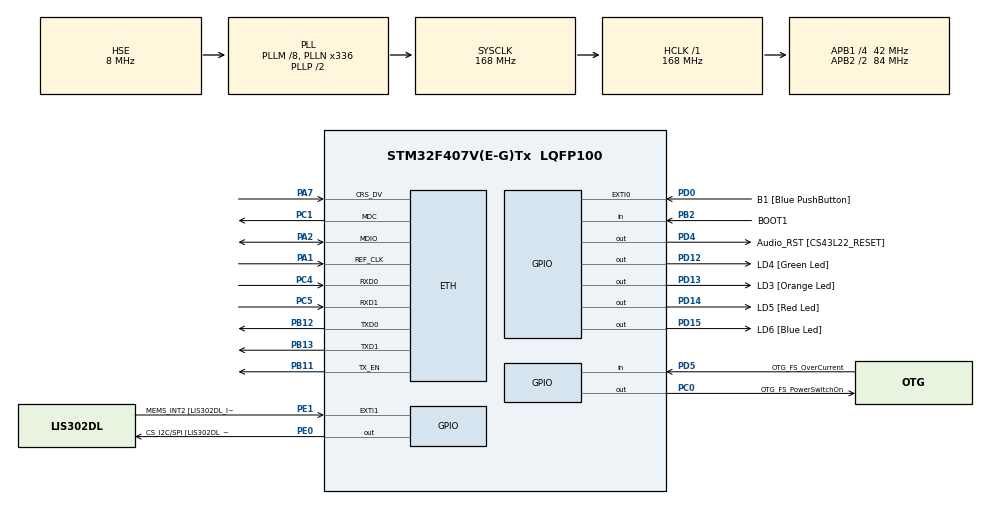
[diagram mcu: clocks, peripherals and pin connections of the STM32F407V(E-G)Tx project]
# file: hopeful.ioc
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ETH.MediaInterface=ETH_MEDIA_INTERFACE_RMII
FREERTOS.Tasks01=defaultTask,0,128,StartDefaultTask
Mcu.Family=STM32F4
Mcu.Name=STM32F407V(E-G)Tx
Mcu.Package=LQFP100
NVIC.ETH_IRQn=true\:5\:0\:false
NVIC.PriorityGroup=NVIC_PRIORITYGROUP_4
PA1.Mode=RMII
PA1.Signal=ETH_REF_CLK
PA10.GPIO_Label=OTG_FS_ID
PA10.GPIO_Mode=GPIO_MODE_AF_PP
PA10.GPIO_PuPd=GPIO_NOPULL
PA10.GPIO_Speed=GPIO_SPEED_LOW
PA10.Signal=USB_OTG_FS_ID
PA11.GPIO_Label=OTG_FS_DM
PA11.GPIO_Mode=GPIO_MODE_AF_PP
PA11.GPIO_PuPd=GPIO_NOPULL
PA11.GPIO_Speed=GPIO_SPEED_LOW
PA11.Signal=USB_OTG_FS_DM
PA12.GPIO_Label=OTG_FS_DP
PA12.GPIO_Mode=GPIO_MODE_AF_PP
PA12.GPIO_PuPd=GPIO_NOPULL
PA12.GPIO_Speed=GPIO_SPEED_LOW
PA12.Signal=USB_OTG_FS_DP
PA13.GPIO_Label=SWDIO
PA13.Mode=Trace-Asynchronous_SW
PA13.Signal=SYS_JTMS-SWDIO
PA14.GPIO_Label=SWCLK
PA14.Mode=Trace-Asynchronous_SW
PA14.Signal=SYS_JTCK-SWCLK
PA2.Mode=RMII
PA2.Signal=ETH_MDIO
PA4.GPIO_Label=I2S3_WS [CS43L22_LRCK]
PA4.GPIO_Mode=GPIO_MODE_AF_PP
PA4.GPIO_PuPd=GPIO_NOPULL
PA4.GPIO_Speed=GPIO_SPEED_LOW
PA4.Signal=I2S3_WS
PA5.GPIO_Label=SPI1_SCK [LIS302DL_SCL/SPC]
PA5.GPIO_Mode=GPIO_MODE_AF_PP
PA5.GPIO_PuPd=GPIO_NOPULL
PA5.GPIO_Speed=GPIO_SPEED_LOW
PA5.Signal=SPI1_SCK
PA6.GPIO_Label=SPI1_MISO [LIS302DL_SDO]
PA6.GPIO_Mode=GPIO_MODE_AF_PP
PA6.GPIO_PuPd=GPIO_NOPULL
PA6.GPIO_Speed=GPIO_SPEED_LOW
PA6.Signal=SPI1_MISO
PA7.Mode=RMII
PA7.Signal=ETH_CRS_DV
PA9.GPIO_Label=VBUS_FS
PA9.GPIO_Mode=GPIO_MODE_INPUT
PA9.GPIO_PuPd=GPIO_NOPULL
PA9.Signal=USB_OTG_FS_VBUS
PB10.GPIO_Label=CLK_IN [MP45DT02_CLK]
PB10.GPIO_Mode=GPIO_MODE_AF_PP
PB10.GPIO_PuPd=GPIO_NOPULL
PB10.GPIO_Speed=GPIO_SPEED_LOW
PB10.Signal=I2S2_CK
PB11.Mode=RMII
PB11.Signal=ETH_TX_EN
PB12.Mode=RMII
PB12.Signal=ETH_TXD0
PB13.Mode=RMII
PB13.Signal=ETH_TXD1
PB15.GPIO_Label=PDM_OUT [MP45DT02_DOUT]
PB15.GPIO_Mode=GPIO_MODE_AF_PP
PB15.GPIO_PuPd=GPIO_NOPULL
PB15.GPIO_Speed=GPIO_SPEED_LOW
PB15.Signal=I2S2_SD
PB2.GPIO_Label=BOOT1
PB2.GPIO_Mode=GPIO_MODE_INPUT
PB2.GPIO_PuPd=GPIO_NOPULL
PB2.Signal=GPIO_Input
PB3.GPIO_Label=SWO
PB3.Mode=Trace-Asynchronous_SW
PB3.Signal=SYS_JTDO-SWO
PB6.GPIO_Label=Audio_SCL [CS43L22_SCL]
PB6.GPIO_Mode=GPIO_MODE_AF_OD
PB6.GPIO_PuPd=GPIO_NOPULL
PB6.GPIO_Speed=GPIO_SPEED_LOW
PB6.Signal=I2C1_SCL
PB9.GPIO_Label=Audio_SDA [CS43L22_SDA]
PB9.GPIO_Mode=GPIO_MODE_AF_OD
PB9.GPIO_PuPd=GPIO_NOPULL
PB9.GPIO_Speed=GPIO_SPEED_LOW
PB9.Signal=I2C1_SDA
PC0.GPIO_Label=OTG_FS_PowerSwitchOn
PC0.GPIO_PuPd=GPIO_NOPULL
PC0.GPIO_Speed=GPIO_SPEED_LOW
PC0.Signal=GPIO_Output
PC1.Mode=RMII
PC1.Signal=ETH_MDC
PC10.GPIO_Label=I2S3_SCK [CS43L22_SCLK]
PC10.GPIO_Mode=GPIO_MODE_AF_PP
PC10.GPIO_PuPd=GPIO_NOPULL
PC10.GPIO_Speed=GPIO_SPEED_LOW
PC10.Signal=I2S3_CK
PC12.GPIO_Label=I2S3_SD [CS43L22_SDIN]
PC12.GPIO_Mode=GPIO_MODE_AF_PP
PC12.GPIO_PuPd=GPIO_NOPULL
PC12.GPIO_Speed=GPIO_SPEED_LOW
PC12.Signal=I2S3_SD
PC14-OSC32_IN.GPIO_Label=PC14-OSC32_IN
PC14-OSC32_IN.Signal=RCC_OSC32_IN
PC15-OSC32_OUT.GPIO_Label=PC15-OSC32_OUT
PC15-OSC32_OUT.Signal=RCC_OSC32_OUT
PC4.Mode=RMII
PC4.Signal=ETH_RXD0
PC5.Mode=RMII
PC5.Signal=ETH_RXD1
PC7.GPIO_Label=I2S3_MCK [CS43L22_MCLK]
PC7.GPIO_Mode=GPIO_MODE_AF_PP
PC7.GPIO_PuPd=GPIO_NOPULL
PC7.GPIO_Speed=GPIO_SPEED_LOW
PC7.Signal=I2S3_MCK
PD0.GPIO_Label=B1 [Blue PushButton]
PD0.GPIO_ModeDefaultEXTI=GPIO_MODE_EVT_RISING
PD0.GPIO_PuPd=GPIO_NOPULL
PD0.Signal=GPXTI0
PD12.GPIO_Label=LD4 [Green Led]
PD12.GPIO_PuPd=GPIO_NOPULL
PD12.GPIO_Speed=GPIO_SPEED_LOW
PD12.Signal=GPIO_Output
PD13.GPIO_Label=LD3 [Orange Led]
PD13.GPIO_PuPd=GPIO_NOPULL
PD13.GPIO_Speed=GPIO_SPEED_LOW
PD13.Signal=GPIO_Output
PD14.GPIO_Label=LD5 [Red Led]
PD14.GPIO_PuPd=GPIO_NOPULL
PD14.GPIO_Speed=GPIO_SPEED_LOW
PD14.Signal=GPIO_Output
PD15.GPIO_Label=LD6 [Blue Led]
PD15.GPIO_PuPd=GPIO_NOPULL
PD15.GPIO_Speed=GPIO_SPEED_LOW
PD15.Signal=GPIO_Output
PD4.GPIO_Label=Audio_RST [CS43L22_RESET]
PD4.GPIO_PuPd=GPIO_NOPULL
PD4.GPIO_Speed=GPIO_SPEED_LOW
PD4.Signal=GPIO_Output
PD5.GPIO_Label=OTG_FS_OverCurrent
PD5.GPIO_Mode=GPIO_MODE_INPUT
PD5.GPIO_PuPd=GPIO_NOPULL
PD5.Signal=GPIO_Input
PE0.GPIO_Label=CS_I2C/SPI [LIS302DL_CS_I2C/SPI]
PE0.GPIO_PuPd=GPIO_NOPULL
PE0.GPIO_Speed=GPIO_SPEED_LOW
PE0.Signal=GPIO_Output
PE1.GPIO_Label=MEMS_INT2 [LIS302DL_INT2]
PE1.GPIO_ModeDefaultEXTI=GPIO_MODE_EVT_RISING
PE1.GPIO_PuPd=GPIO_NOPULL
PE1.Signal=GPXTI1
PH0-OSC_IN.GPIO_Label=PH0-OSC_IN
PH0-OSC_IN.Mode=HSE-External-Oscillator
PH0-OSC_IN.Signal=RCC_OSC_IN
PH1-OSC_OUT.GPIO_Label=PH1-OSC_OUT
PH1-OSC_OUT.Mode=HSE-External-Oscillator
PH1-OSC_OUT.Signal=RCC_OSC_OUT
ProjectManager.TargetToolchain=TrueSTUDIO
RCC.AHBFreq_Value=168000000
RCC.APB1CLKDivider=RCC_HCLK_DIV4
RCC.APB1Freq_Value=42000000
RCC.APB1TimFreq_Value=84000000
RCC.APB2CLKDivider=RCC_HCLK_DIV2
RCC.APB2Freq_Value=84000000
RCC.APB2TimFreq_Value=168000000
RCC.CortexFreq_Value=168000000
RCC.HCLKFreq_Value=168000000
RCC.HSE_VALUE=8000000
RCC.HSI_VALUE=16000000
RCC.LSE_VALUE=32768
RCC.PLLM=8
RCC.PLLN=336
RCC.PLLQ=7
RCC.PLLSourceVirtual=RCC_PLLSOURCE_HSE
RCC.SYSCLKFreq_VALUE=168000000
RCC.SYSCLKSource=RCC_SYSCLKSOURCE_PLLCLK
RCC.VCOOutputFreq_Value=336000000
VP_FREERTOS_VS_ENABLE.Mode=Enabled
VP_LWIP_VS_Enabled.Mode=Enabled
board=STM32F4DISCOVERY

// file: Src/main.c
/**
  ******************************************************************************
  * File Name          : main.c
  * Description        : Main program body
  ******************************************************************************
  *
  * COPYRIGHT(c) 2015 STMicroelectronics
  *
  * Redistribution and use in source and binary forms, with or without modification,
  * are permitted provided that the following conditions are met:
  *   1. Redistributions of source code must retain the above copyright notice,
  *      this list of conditions and the following disclaimer.
  *   2. Redistributions in binary form must reproduce the above copyright notice,
  *      this list of conditions and the following disclaimer in the documentation
  *      and/or other materials provided with the distribution.
  *   3. Neither the name of STMicroelectronics nor the names of its contributors
  *      may be used to endorse or promote products derived from this software
  *      without specific prior written permission.
  *
  * THIS SOFTWARE IS PROVIDED BY THE COPYRIGHT HOLDERS AND CONTRIBUTORS "AS IS"
  * AND ANY EXPRESS OR IMPLIED WARRANTIES, INCLUDING, BUT NOT LIMITED TO, THE
  * IMPLIED WARRANTIES OF MERCHANTABILITY AND FITNESS FOR A PARTICULAR PURPOSE ARE
  * DISCLAIMED. IN NO EVENT SHALL THE COPYRIGHT HOLDER OR CONTRIBUTORS BE LIABLE
  * FOR ANY DIRECT, INDIRECT, INCIDENTAL, SPECIAL, EXEMPLARY, OR CONSEQUENTIAL
  * DAMAGES (INCLUDING, BUT NOT LIMITED TO, PROCUREMENT OF SUBSTITUTE GOODS OR
  * SERVICES; LOSS OF USE, DATA, OR PROFITS; OR BUSINESS INTERRUPTION) HOWEVER
  * CAUSED AND ON ANY THEORY OF LIABILITY, WHETHER IN CONTRACT, STRICT LIABILITY,
  * OR TORT (INCLUDING NEGLIGENCE OR OTHERWISE) ARISING IN ANY WAY OUT OF THE USE
  * OF THIS SOFTWARE, EVEN IF ADVISED OF THE POSSIBILITY OF SUCH DAMAGE.
  *
  ******************************************************************************
  */
#include "stm32f4xx_hal.h"
#include "cmsis_os.h"
#include "lwip.h"

/* USER CODE BEGIN Includes */
//#include "tcp.h"
#include "sockets.h"

/* USER CODE END Includes */

osThreadId defaultTaskHandle;

/* USER CODE BEGIN PV */
/* Private variables ---------------------------------------------------------*/

/* USER CODE END PV */

void SystemClock_Config(void);
static void MX_GPIO_Init(void);
void StartDefaultTask(void const * argument);

/* USER CODE BEGIN PFP */
/* Private function prototypes -----------------------------------------------*/

/* USER CODE END PFP */

/* USER CODE BEGIN 0 */
//static err_t tcp_echo(void *arg, struct tcp_pcb *newpcb, err_t err){
//
//	//do things
//	return ERR_OK;
//
//}
/* USER CODE END 0 */

int main(void)
{

  /* MCU Configuration----------------------------------------------------------*/

  /* Reset of all peripherals, Initializes the Flash interface and the Systick. */
  HAL_Init();

  /* Configure the system clock */
  SystemClock_Config();

  /* Initialize all configured peripherals */
  MX_GPIO_Init();

  /* Create the thread(s) */
  /* definition and creation of defaultTask */
  osThreadDef(defaultTask, StartDefaultTask, osPriorityNormal, 0, 128);
  defaultTaskHandle = osThreadCreate(osThread(defaultTask), NULL);

  /* Start scheduler */
  osKernelStart();

  /* We should never get here as control is now taken by the scheduler */

  /* Infinite loop */
  /* USER CODE BEGIN WHILE */

//    struct tcp_pcb * conn = tcp_new();
//    err_t err = tcp_bind(conn, IP_ADDR_ANY, 8360);
//
//    if (err == ERR_OK){
//    	conn = tcp_listen(conn);
//    	tcp_accept(conn, tcp_echo);
//
//
//    }

  while (1)
  {

  /* USER CODE END WHILE */

  }

}

/** System Clock Configuration
*/
void SystemClock_Config(void)
{

  RCC_OscInitTypeDef RCC_OscInitStruct;
  RCC_ClkInitTypeDef RCC_ClkInitStruct;

  __PWR_CLK_ENABLE();

  __HAL_PWR_VOLTAGESCALING_CONFIG(PWR_REGULATOR_VOLTAGE_SCALE1);

  RCC_OscInitStruct.OscillatorType = RCC_OSCILLATORTYPE_HSE;
  RCC_OscInitStruct.HSEState = RCC_HSE_ON;
  RCC_OscInitStruct.PLL.PLLState = RCC_PLL_ON;
  RCC_OscInitStruct.PLL.PLLSource = RCC_PLLSOURCE_HSE;
  RCC_OscInitStruct.PLL.PLLM = 8;
  RCC_OscInitStruct.PLL.PLLN = 336;
  RCC_OscInitStruct.PLL.PLLP = RCC_PLLP_DIV2;
  RCC_OscInitStruct.PLL.PLLQ = 7;
  HAL_RCC_OscConfig(&RCC_OscInitStruct);

  RCC_ClkInitStruct.ClockType = RCC_CLOCKTYPE_SYSCLK|RCC_CLOCKTYPE_PCLK1
                              |RCC_CLOCKTYPE_PCLK2;
  RCC_ClkInitStruct.SYSCLKSource = RCC_SYSCLKSOURCE_PLLCLK;
  RCC_ClkInitStruct.AHBCLKDivider = RCC_SYSCLK_DIV1;
  RCC_ClkInitStruct.APB1CLKDivider = RCC_HCLK_DIV4;
  RCC_ClkInitStruct.APB2CLKDivider = RCC_HCLK_DIV2;
  HAL_RCC_ClockConfig(&RCC_ClkInitStruct, FLASH_LATENCY_5);

  HAL_SYSTICK_Config(HAL_RCC_GetHCLKFreq()/1000);

  HAL_SYSTICK_CLKSourceConfig(SYSTICK_CLKSOURCE_HCLK);

  /* SysTick_IRQn interrupt configuration */
  HAL_NVIC_SetPriority(SysTick_IRQn, 0, 0);
}

/** Configure pins as
        * Analog
        * Input
        * Output
        * EVENT_OUT
        * EXTI
     PA4   ------> I2S3_WS
     PA5   ------> SPI1_SCK
     PA6   ------> SPI1_MISO
     PB10   ------> I2S2_CK
     PB15   ------> I2S2_SD
     PC7   ------> I2S3_MCK
     PA9   ------> USB_OTG_FS_VBUS
     PA10   ------> USB_OTG_FS_ID
     PA11   ------> USB_OTG_FS_DM
     PA12   ------> USB_OTG_FS_DP
     PC10   ------> I2S3_CK
     PC12   ------> I2S3_SD
     PB6   ------> I2C1_SCL
     PB9   ------> I2C1_SDA
*/
void MX_GPIO_Init(void)
{

  GPIO_InitTypeDef GPIO_InitStruct;

  /* GPIO Ports Clock Enable */
  __GPIOC_CLK_ENABLE();
  __GPIOH_CLK_ENABLE();
  __GPIOA_CLK_ENABLE();
  __GPIOB_CLK_ENABLE();
  __GPIOD_CLK_ENABLE();
  __GPIOE_CLK_ENABLE();

  /*Configure GPIO pin : OTG_FS_PowerSwitchOn_Pin */
  GPIO_InitStruct.Pin = OTG_FS_PowerSwitchOn_Pin;
  GPIO_InitStruct.Mode = GPIO_MODE_OUTPUT_PP;
  GPIO_InitStruct.Pull = GPIO_NOPULL;
  GPIO_InitStruct.Speed = GPIO_SPEED_LOW;
  HAL_GPIO_Init(OTG_FS_PowerSwitchOn_GPIO_Port, &GPIO_InitStruct);

  /*Configure GPIO pin : PA4 */
  GPIO_InitStruct.Pin = GPIO_PIN_4;
  GPIO_InitStruct.Mode = GPIO_MODE_AF_PP;
  GPIO_InitStruct.Pull = GPIO_NOPULL;
  GPIO_InitStruct.Speed = GPIO_SPEED_LOW;
  GPIO_InitStruct.Alternate = GPIO_AF6_SPI3;
  HAL_GPIO_Init(GPIOA, &GPIO_InitStruct);

  /*Configure GPIO pins : PA5 PA6 */
  GPIO_InitStruct.Pin = GPIO_PIN_5|GPIO_PIN_6;
  GPIO_InitStruct.Mode = GPIO_MODE_AF_PP;
  GPIO_InitStruct.Pull = GPIO_NOPULL;
  GPIO_InitStruct.Speed = GPIO_SPEED_LOW;
  GPIO_InitStruct.Alternate = GPIO_AF5_SPI1;
  HAL_GPIO_Init(GPIOA, &GPIO_InitStruct);

  /*Configure GPIO pin : BOOT1_Pin */
  GPIO_InitStruct.Pin = BOOT1_Pin;
  GPIO_InitStruct.Mode = GPIO_MODE_INPUT;
  GPIO_InitStruct.Pull = GPIO_NOPULL;
  HAL_GPIO_Init(BOOT1_GPIO_Port, &GPIO_InitStruct);

  /*Configure GPIO pins : CLK_IN_Pin PDM_OUT_Pin */
  GPIO_InitStruct.Pin = CLK_IN_Pin|PDM_OUT_Pin;
  GPIO_InitStruct.Mode = GPIO_MODE_AF_PP;
  GPIO_InitStruct.Pull = GPIO_NOPULL;
  GPIO_InitStruct.Speed = GPIO_SPEED_LOW;
  GPIO_InitStruct.Alternate = GPIO_AF5_SPI2;
  HAL_GPIO_Init(GPIOB, &GPIO_InitStruct);

  /*Configure GPIO pins : LD4_Pin LD3_Pin LD5_Pin LD6_Pin
                           Audio_RST_Pin */
  GPIO_InitStruct.Pin = LD4_Pin|LD3_Pin|LD5_Pin|LD6_Pin
                          |Audio_RST_Pin;
  GPIO_InitStruct.Mode = GPIO_MODE_OUTPUT_PP;
  GPIO_InitStruct.Pull = GPIO_NOPULL;
  GPIO_InitStruct.Speed = GPIO_SPEED_LOW;
  HAL_GPIO_Init(GPIOD, &GPIO_InitStruct);

  /*Configure GPIO pins : PC7 I2S3_SCK_Pin PC12 */
  GPIO_InitStruct.Pin = GPIO_PIN_7|I2S3_SCK_Pin|GPIO_PIN_12;
  GPIO_InitStruct.Mode = GPIO_MODE_AF_PP;
  GPIO_InitStruct.Pull = GPIO_NOPULL;
  GPIO_InitStruct.Speed = GPIO_SPEED_LOW;
  GPIO_InitStruct.Alternate = GPIO_AF6_SPI3;
  HAL_GPIO_Init(GPIOC, &GPIO_InitStruct);

  /*Configure GPIO pin : VBUS_FS_Pin */
  GPIO_InitStruct.Pin = VBUS_FS_Pin;
  GPIO_InitStruct.Mode = GPIO_MODE_INPUT;
  GPIO_InitStruct.Pull = GPIO_NOPULL;
  HAL_GPIO_Init(VBUS_FS_GPIO_Port, &GPIO_InitStruct);

  /*Configure GPIO pins : OTG_FS_ID_Pin OTG_FS_DM_Pin OTG_FS_DP_Pin */
  GPIO_InitStruct.Pin = OTG_FS_ID_Pin|OTG_FS_DM_Pin|OTG_FS_DP_Pin;
  GPIO_InitStruct.Mode = GPIO_MODE_AF_PP;
  GPIO_InitStruct.Pull = GPIO_NOPULL;
  GPIO_InitStruct.Speed = GPIO_SPEED_LOW;
  GPIO_InitStruct.Alternate = GPIO_AF10_OTG_FS;
  HAL_GPIO_Init(GPIOA, &GPIO_InitStruct);

  /*Configure GPIO pin : B1_Pin */
  GPIO_InitStruct.Pin = B1_Pin;
  GPIO_InitStruct.Mode = GPIO_MODE_EVT_RISING;
  GPIO_InitStruct.Pull = GPIO_NOPULL;
  HAL_GPIO_Init(B1_GPIO_Port, &GPIO_InitStruct);

  /*Configure GPIO pin : OTG_FS_OverCurrent_Pin */
  GPIO_InitStruct.Pin = OTG_FS_OverCurrent_Pin;
  GPIO_InitStruct.Mode = GPIO_MODE_INPUT;
  GPIO_InitStruct.Pull = GPIO_NOPULL;
  HAL_GPIO_Init(OTG_FS_OverCurrent_GPIO_Port, &GPIO_InitStruct);

  /*Configure GPIO pins : Audio_SCL_Pin Audio_SDA_Pin */
  GPIO_InitStruct.Pin = Audio_SCL_Pin|Audio_SDA_Pin;
  GPIO_InitStruct.Mode = GPIO_MODE_AF_OD;
  GPIO_InitStruct.Pull = GPIO_PULLUP;
  GPIO_InitStruct.Speed = GPIO_SPEED_LOW;
  GPIO_InitStruct.Alternate = GPIO_AF4_I2C1;
  HAL_GPIO_Init(GPIOB, &GPIO_InitStruct);

  /*Configure GPIO pin : CS_I2C_SPI_Pin */
  GPIO_InitStruct.Pin = CS_I2C_SPI_Pin;
  GPIO_InitStruct.Mode = GPIO_MODE_OUTPUT_PP;
  GPIO_InitStruct.Pull = GPIO_NOPULL;
  GPIO_InitStruct.Speed = GPIO_SPEED_LOW;
  HAL_GPIO_Init(CS_I2C_SPI_GPIO_Port, &GPIO_InitStruct);

  /*Configure GPIO pin : MEMS_INT2_Pin */
  GPIO_InitStruct.Pin = MEMS_INT2_Pin;
  GPIO_InitStruct.Mode = GPIO_MODE_EVT_RISING;
  GPIO_InitStruct.Pull = GPIO_NOPULL;
  HAL_GPIO_Init(MEMS_INT2_GPIO_Port, &GPIO_InitStruct);

}

/* StartDefaultTask function */
void StartDefaultTask(void const * argument)
{
  /* init code for LWIP */
  MX_LWIP_Init();

  /* USER CODE BEGIN 5 */

  int sock = socket(AF_INET, SOCK_STREAM, 0);

  struct sockaddr_in addr;
  addr.sin_family = AF_INET;
  addr.sin_port = htons(8360);
  addr.sin_addr.s_addr = INADDR_ANY;
  err_t bind_ret = connect(sock, (struct sockaddr *) &addr, sizeof(addr) );

//  struct sockaddr_in dest;
//  dest.sin_family = AF_INET;
//  dest.sin_port = htons(8360);
//  dest.sin_addr.s_addr = inet_addr("123.123.123.123");

//  err_t lis_ret = listen(sock, TCP_LISTEN_BACKLOG);

//  uint8_t * sendbuffer = (uint8_t * ) malloc(250);
  uint8_t * recbuffer = (uint8_t *) malloc(300);

  recv(sock, recbuffer, 300, 0);

  char a = 'G';

  /* Infinite loop */
  for(;;)
  {

//	accept(sock, (struct sockaddr *) &addr, sizeof(addr));
//	read(sock, recbuffer, 300);
//	err_t err = sendto(sock, &a, sizeof(a), 0, (struct sockaddr *) &dest, sizeof(dest));
//	osDelay(1);
  }
  /* USER CODE END 5 */
}

/************************ (C) COPYRIGHT STMicroelectronics *****END OF FILE****/
